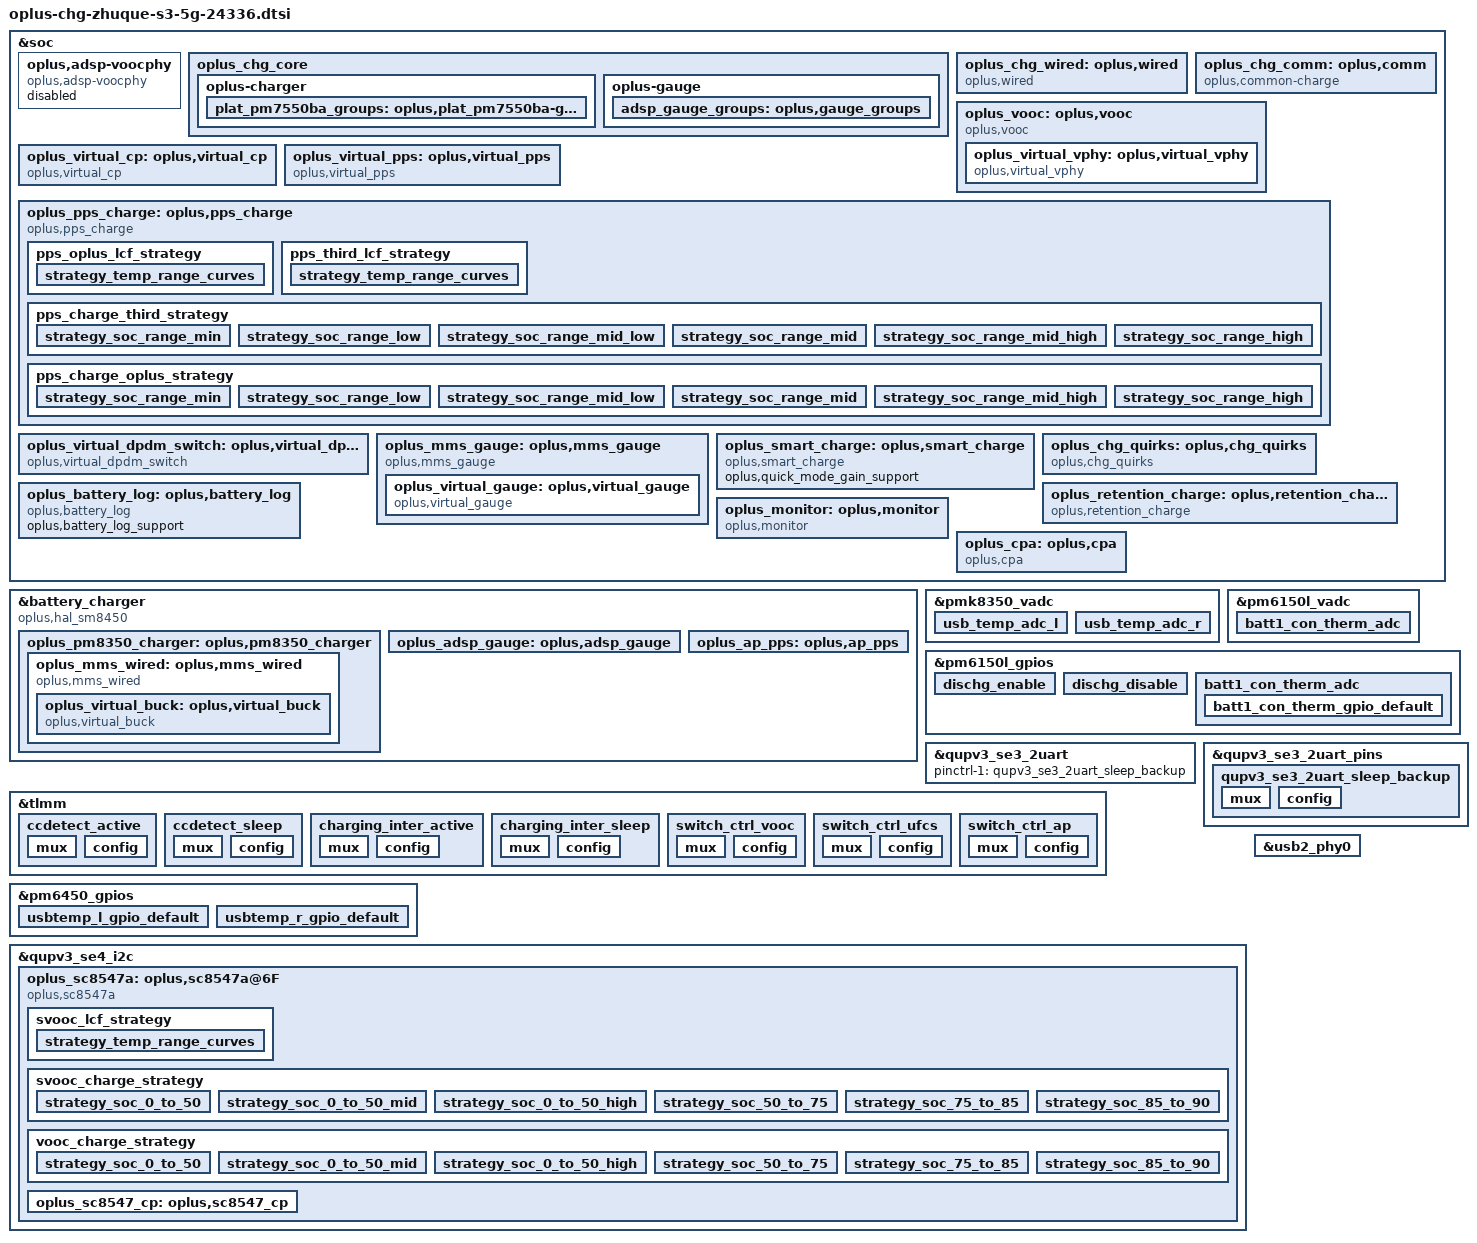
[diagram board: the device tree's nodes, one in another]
#include "oplus_chg.dtsi"

&soc {
	oplus,adsp-voocphy {
		status = "disabled";
		compatible = "oplus,adsp-voocphy";
	};

	oplus_chg_core {
		oplus,chg_framework_v2;
		oplus,smart_charging_screenoff;
		oplus,chg_spec_version = <OPLUS_CHG_SPEC_VER_V3P7>;

		oplus-charger {
			plat_pm7550ba_groups: oplus,plat_pm7550ba-groups {
				functions = <
					OPLUS_IC_FUNC_INIT
					OPLUS_IC_FUNC_EXIT
					OPLUS_IC_FUNC_REG_DUMP
					OPLUS_IC_FUNC_SMT_TEST
					OPLUS_IC_FUNC_BUCK_INPUT_PRESENT
					OPLUS_IC_FUNC_BUCK_INPUT_SUSPEND
					OPLUS_IC_FUNC_BUCK_INPUT_IS_SUSPEND
					OPLUS_IC_FUNC_BUCK_OUTPUT_SUSPEND
					OPLUS_IC_FUNC_BUCK_OUTPUT_IS_SUSPEND
					OPLUS_IC_FUNC_BUCK_GET_CC_ORIENTATION
					OPLUS_IC_FUNC_BUCK_GET_CHARGER_TYPE
					OPLUS_IC_FUNC_BUCK_RERUN_BC12
					OPLUS_IC_FUNC_BUCK_QC_DETECT_ENABLE
					OPLUS_IC_FUNC_BUCK_SHIPMODE_ENABLE
					OPLUS_IC_FUNC_BUCK_SET_QC_CONFIG
					OPLUS_IC_FUNC_BUCK_SET_PD_CONFIG
					OPLUS_IC_FUNC_BACKUP_SOC
					OPLUS_IC_FUNC_GET_SHUTDOWN_SOC
					OPLUS_IC_FUNC_GET_TYPEC_MODE
					OPLUS_IC_FUNC_BUCK_SET_ICL
					OPLUS_IC_FUNC_BUCK_GET_ICL
					OPLUS_IC_FUNC_BUCK_SET_FCC
					OPLUS_IC_FUNC_BUCK_SET_FV
					OPLUS_IC_FUNC_BUCK_SET_ITERM
					OPLUS_IC_FUNC_BUCK_SET_RECHG_VOL
					OPLUS_IC_FUNC_BUCK_GET_INPUT_CURR
					OPLUS_IC_FUNC_BUCK_GET_INPUT_VOL
					OPLUS_IC_FUNC_GET_CHARGER_CYCLE
					OPLUS_IC_FUNC_OTG_BOOST_ENABLE
					OPLUS_IC_FUNC_BUCK_GET_VBUS_COLLAPSE_STATUS
					OPLUS_IC_FUNC_GET_OTG_ENABLE
					OPLUS_IC_FUNC_SET_OTG_SWITCH_STATUS
					OPLUS_IC_FUNC_GET_OTG_SWITCH_STATUS
					OPLUS_IC_FUNC_GET_OTG_ONLINE_STATUS
					OPLUS_IC_FUNC_BUCK_GET_HW_DETECT
					OPLUS_IC_FUNC_VOOCPHY_SET_MATCH_TEMP
					OPLUS_IC_FUNC_IS_OPLUS_SVID
					OPLUS_IC_FUNC_BUCK_GET_USB_BTB_TEMP
					OPLUS_IC_FUNC_BUCK_GET_BATT_BTB_TEMP
					OPLUS_IC_FUNC_SET_TYPEC_MODE
					OPLUS_IC_FUNC_GET_TYPEC_ROLE
				>;
				virqs = <
					OPLUS_IC_VIRQ_ERR
					OPLUS_IC_VIRQ_CC_DETECT
					OPLUS_IC_VIRQ_PLUGIN
					OPLUS_IC_VIRQ_CC_CHANGED
					OPLUS_IC_VIRQ_CHG_TYPE_CHANGE
					OPLUS_IC_VIRQ_SVID
					OPLUS_IC_VIRQ_OTG_ENABLE
				>;
			};
		};

		oplus-gauge {
			adsp_gauge_groups: oplus,gauge_groups {
				functions = <
					OPLUS_IC_FUNC_INIT
					OPLUS_IC_FUNC_EXIT
					OPLUS_IC_FUNC_REG_DUMP
					OPLUS_IC_FUNC_SMT_TEST
					OPLUS_IC_FUNC_GAUGE_GET_BATT_VOL
					OPLUS_IC_FUNC_GAUGE_GET_BATT_MAX
					OPLUS_IC_FUNC_GAUGE_GET_BATT_MIN
					OPLUS_IC_FUNC_GAUGE_GET_BATT_CURR
					OPLUS_IC_FUNC_GAUGE_GET_BATT_TEMP
					OPLUS_IC_FUNC_GAUGE_GET_BATT_SOC
					OPLUS_IC_FUNC_GAUGE_GET_BATT_FCC
					OPLUS_IC_FUNC_GAUGE_GET_BATT_CC
					OPLUS_IC_FUNC_GAUGE_GET_BATT_RM
					OPLUS_IC_FUNC_GAUGE_GET_BATT_SOH
					OPLUS_IC_FUNC_GAUGE_GET_BATT_HMAC
					OPLUS_IC_FUNC_GAUGE_SET_BATT_FULL
					OPLUS_IC_FUNC_GAUGE_UPDATE_DOD0
					OPLUS_IC_FUNC_GAUGE_UPDATE_SOC_SMOOTH
					OPLUS_IC_FUNC_GAUGE_GET_CB_STATUS
					OPLUS_IC_FUNC_GAUGE_GET_BATT_NUM
					OPLUS_IC_FUNC_GAUGE_GET_DEVICE_TYPE
					OPLUS_IC_FUNC_GAUGE_GET_DEVICE_TYPE_FOR_VOOC
					OPLUS_IC_FUNC_GAUGE_GET_BATT_FCC
					OPLUS_IC_FUNC_GAUGE_UPDATE
					OPLUS_IC_FUNC_GAUGE_IS_SUSPEND
					OPLUS_IC_FUNC_GAUGE_GET_BATT_AUTH
					OPLUS_IC_FUNC_GAUGE_GET_BCC_PARMS
					OPLUS_IC_FUNC_GAUGE_GET_DEVICE_TYPE_FOR_BCC
					OPLUS_IC_FUNC_GAUGE_GET_DOD0
					OPLUS_IC_FUNC_GAUGE_GET_DOD0_PASSED_Q
					OPLUS_IC_FUNC_GAUGE_GET_QMAX
					OPLUS_IC_FUNC_GAUGE_GET_QMAX_PASSED_Q
					OPLUS_IC_FUNC_GAUGE_GET_DEC_FG_TYPE
					OPLUS_IC_FUNC_GAUGE_GET_DEC_CV_SOH
					OPLUS_IC_FUNC_GAUGE_SET_VCT
					OPLUS_IC_FUNC_GAUGE_GET_VCT
				>;
				virqs = <
					OPLUS_IC_VIRQ_ERR
					OPLUS_IC_VIRQ_OFFLINE
					OPLUS_IC_VIRQ_RESUME
				>;
			};
		};

	};

	oplus_chg_wired: oplus,wired {
		compatible = "oplus,wired";
		oplus,vooc-support;

		oplus_spec,vbatt_pdqc_to_9v_thr = <5000>;
		oplus_spec,pd-iclmax-ma = <1500>;
		oplus_spec,qc-iclmax-ma = <1500>;
		oplus_spec,non-standard-ibatmax-ma = <1000>;
		oplus_spec,input-power-mw = <
			2500		/* OPLUS_WIRED_CHG_MODE_UNKNOWN */
			2500		/* OPLUS_WIRED_CHG_MODE_SDP */
			7500		/* OPLUS_WIRED_CHG_MODE_CDP */
			10000		/* OPLUS_WIRED_CHG_MODE_DCP */
			30000		/* OPLUS_WIRED_CHG_MODE_VOOC */
			13500		/* OPLUS_WIRED_CHG_MODE_QC */
			13500		/* OPLUS_WIRED_CHG_MODE_PD */
		>;
		oplus_spec,led_on-fccmax-ma = <0 883 3300 3300 3300 3300 3300 1000 0>;
		oplus_spec,fccmax-ma-lv = <
			0 1555 2200 2200 2200 2200 2200 2200 0	/* OPLUS_WIRED_CHG_MODE_UNKNOWN */
			0 600  600  600  600  600  600  600  0	/* OPLUS_WIRED_CHG_MODE_SDP */
			0 883 1600 1600 1600 1600 1600 1600 0	/* OPLUS_WIRED_CHG_MODE_CDP */
			0 883 2200 2200 2200 2200 2200 2200 0	/* OPLUS_WIRED_CHG_MODE_DCP */
			0 883 3300 3300 3300 3300 3300 3239 0	/* OPLUS_WIRED_CHG_MODE_VOOC */
			0 883 3300 3300 3300 3300 3300 3239 0	/* OPLUS_WIRED_CHG_MODE_QC */
			0 883 3300 3300 3300 3300 3300 3239 0	/* OPLUS_WIRED_CHG_MODE_PD */
		>;
		oplus_spec,fccmax-ma-hv = <
			0 1555 2200 2200 2200 2200 2200 2200 0	/* OPLUS_WIRED_CHG_MODE_UNKNOWN */
			0 600  600  600  600  600  600  600  0	/* OPLUS_WIRED_CHG_MODE_SDP */
			0 883  1600 1600 1600 1600 1600 1600 0	/* OPLUS_WIRED_CHG_MODE_CDP */
			0 883  2200 2200 2200 2200 2200 2200 0	/* OPLUS_WIRED_CHG_MODE_DCP */
			0 883 2650 3300 3300 3300 3300 3300 0	/* OPLUS_WIRED_CHG_MODE_VOOC */
			0 883  2650 3300 3300 3300 3300 3300 0	/* OPLUS_WIRED_CHG_MODE_QC */
			0 883  2650 3300 3300 3300 3300 3300 0	/* OPLUS_WIRED_CHG_MODE_PD */
		>;

		oplus_spec,cool_down_pdqc_vol_mv = <5000 5000 5000 9000>;
		oplus_spec,cool_down_pdqc_curr_ma = <1200 1500 2000 1500>;
		oplus_spec,cool_down_vooc_curr_ma = <1200 1500 2000 2500 3000 3000>;
		oplus_spec,cool_down_normal_curr_ma = <1200 1500 2000>;

		oplus_spec,vbus_ov_thr_mv = <11000 11000>;
		oplus_spec,vbus_uv_thr_mv = <4300 4300>;

		/* first data is strategy used temp type */
		oplus,vooc_strategy_name = "cgcl";
		oplus,vooc_strategy_data = <OPLUS_STRATEGY_USE_BATT_TEMP
					    0   385 3000 1 0
					    385 420 3000 2 0
					    420 440 2000 2 1>;
	};

	oplus_chg_comm: oplus,comm {
		compatible = "oplus,common-charge";
		oplus_spec,dec_step = <20>;
		oplus_spec,dec-vol-cc-full-thr = <0 400 600 800 1000 1200>;
		oplus_spec,dec-vol-fv-full-mv = <0 20 20 40 40 40>;
		oplus_spec,batt-them-thr = <(-100) 0 50 120 160 350 450 530>;
		oplus_spec,iterm-ma = <321>;
		oplus_spec,fv-mv = <4490 4490 4490 4490 4490 4490 4470 4130 4130>;
		oplus_spec,sw-fv-mv = <4440 4440 4440 4440 4440 4440 4420 4080 4080>;
		oplus_spec,hw-fv-inc-mv = <0 18 18 18 18 18 18 18 0>;
		oplus_spec,sw-over-fv-mv = <4500 4500 4500 4500 4500 4500 4480 4140 4140>;
		oplus_spec,sw-over-fv-dec-mv = <8>;
		oplus_spec,non-standard-sw-fv-mv = <3930>;
		oplus_spec,non-standard-fv-mv = <3980>;
		oplus_spec,non-standard-hw-fv-inc-mv = <18>;
		oplus_spec,non-standard-sw-over-fv-mv = <3990>;
		oplus_spec,non-standard-vbatdet-mv = <3680>;
		oplus_spec,wired-vbatdet-mv = <0 4200 4300 4400 4400 4400 4375 4030 0>;
		/* oplus_spec,wls-vbatdet-mv = <0 3675 4235 4370 4370 4370 4030 0>; */
		oplus_spec,fcc-gear-thr-mv = <4180>;
		oplus_spec,vbatt-ov-thr-mv = <4600>;

		oplus_spec,full_pre_ffc_judge;
		oplus_spec,full-pre-ffc-mv = <4485>;
		oplus_spec,ffc-temp-thr = <120 210 350 430>;
		oplus_spec,wired-ffc-step-max = <2>;
		oplus_spec,wired-ffc-fv-mv = <4630 4630>;
		oplus_spec,wired-ffc-fv-cutoff-mv = <4535 4535 4520 4535 4535 4495>;

		oplus_spec,removed_bat_decidegc = <390>;

		oplus_spec,wired-ffc-fcc-ma = <1500 1500 1500
					       1000  1390  1000>;
		oplus_spec,wired-ffc-fcc-cutoff-ma = <1300 1300 1300
						      900 1290 900>;

		oplus_spec,vbat_uv_thr_mv = <3300>;
		oplus_spec,vbat_charging_uv_thr_mv = <3200>;

		/*If use subboard NTC as battery temp, config it as 20, otherwise 0 */
		oplus_spec,tbatt_power_off_cali_temp = <0>;
		oplus,vooc_show_ui_soc_decimal;
		oplus_spec,poweroff_high_batt_temp = <720>;
		oplus_spec,poweroff_emergency_batt_temp = <770>;
		oplus,ui_soc_decimal_speedmin = <20>;

		oplus,gauge_stuck_jump_support;
		oplus,gauge_stuck_threshold = <15>;
		oplus,gauge_stuck_time = <50>;

		oplus,smooth_switch;
		oplus,reserve_chg_soc = <2>;
	};

	oplus_vooc: oplus,vooc {
		compatible = "oplus,vooc";
		oplus,vooc_ic = <&oplus_virtual_vphy>;

		oplus_spec,vooc_soc_range = <50 75 85>;
		oplus_spec,vooc_temp_range = <50 120 180 350 450>;

		oplus,vooc_data_width = <7>;
		oplus,vooc_curr_max = <CP_CURR_LIMIT_7BIT_9_0A>;  /* 45W: 11V 4.1A */
		oplus,vooc_project = <21>; /* 45W 11v4.1A */
		oplus,vooc_curr_table_type = <VOOC_CP_CURR_TABLE>;
		oplus,vooc_power_max_w = <45>;
		oplus,voocphy_support = <2>; /* AP_SINGL_CP_VOOCPHY */
		oplus,support_fake_vooc_check;
		oplus,subboard_ntc_abnormal_current = <4000>;

		oplus,abnormal_adapter_current = <CURR_LIMIT_7BIT_7_5A CURR_LIMIT_7BIT_7_5A
						CURR_LIMIT_7BIT_5_0A CURR_LIMIT_7BIT_5_0A
						CURR_LIMIT_7BIT_4_0A CURR_LIMIT_7BIT_4_0A
						CURR_LIMIT_7BIT_3_0A CURR_LIMIT_7BIT_3_0A
						CURR_LIMIT_7BIT_2_0A CURR_LIMIT_7BIT_2_0A>;


		/* first data is strategy used temp type */
		oplus,general_strategy_name = "cgcl";
		oplus,general_strategy_data = < OPLUS_STRATEGY_USE_SHELL_TEMP
						0   400 CURR_LIMIT_7BIT_7_5A 1 0
						390 420 CURR_LIMIT_7BIT_5_0A 2 0
						410 430 CURR_LIMIT_7BIT_4_0A 3 1
						420 440 CURR_LIMIT_7BIT_3_0A 3 2 >;

		oplus_virtual_vphy: oplus,virtual_vphy {
			compatible = "oplus,virtual_vphy";
			oplus,vphy_ic = <&oplus_sc8547a>;
			oplus,dpdm_switch_ic = <&oplus_virtual_dpdm_switch>;

			oplus,ic_type = <OPLUS_CHG_IC_VIRTUAL_VPHY>;
			oplus,ic_index = <0>;
		};
	};

	oplus_virtual_cp: oplus,virtual_cp {
		compatible = "oplus,virtual_cp";

		oplus,ic_type = <OPLUS_CHG_IC_VIRTUAL_CP>;
		oplus,ic_index = <0>;

		oplus,cp_ic = <&oplus_sc8547_cp>;
		oplus,input_curr_max_ma = <3000>;

		oplus,cp_ic_connect = <OPLUS_CHG_IC_CONNECT_PARALLEL>;
		oplus,main_cp = <0>;
	};

	oplus_virtual_pps: oplus,virtual_pps {
		compatible = "oplus,virtual_pps";

		oplus,ic_type = <OPLUS_CHG_IC_VIRTUAL_PPS>;
		oplus,ic_index = <0>;
		oplus,pps_ic = <&oplus_ap_pps>;
	};
	oplus_pps_charge: oplus,pps_charge {
		compatible = "oplus,pps_charge";
		oplus,pps_ic = <&oplus_virtual_pps>;
		oplus,cp_ic = <&oplus_virtual_cp>;
		oplus,dpdm_switch_ic = <&oplus_virtual_dpdm_switch>;
		oplus,target_vbus_mv = <11000>;
		oplus,curr_max_ma = <3000>;
		oplus,lift_vbus_use_cpvout;
		oplus,process_close_cp_item;
		oplus,curr_max_ma_percent = <2000 /* 75% ibus */
					     1000 /* 85% ibus */>;
		oplus,pps_warm_allow_vol = <4000>;
		oplus,pps_warm_allow_soc = <50>;
		oplus,pps_strategy_normal_current = <3000>;
		oplus,pps_over_high_or_low_current = <3000>;
		oplus,pps_timeout_third = <15145>;
		oplus,pps_timeout_oplus = <15145>;
		oplus,pps_ibat_over_third = <7400>;
		oplus,pps_ibat_over_oplus = <7400>;
		oplus,pps_full_cool_sw_vbat = <4490>;
		oplus,pps_full_normal_sw_vbat = <4490>;
		oplus,pps_full_normal_hw_vbat = <4500>;
		oplus,pps_full_ffc_vbat = <4510>;
		oplus,pps_full_warm_vbat = <4130>;
		oplus,pps_full_cool_sw_vbat_third = <4490>;
		oplus,pps_full_normal_sw_vbat_third= <4490>;
		oplus,pps_full_normal_hw_vbat_third = <4500>;
		oplus,pps_current_change_timeout = <100>;

		oplus,curve_strategy_name = "pps_ufcs_curve_v2";
		oplus,pps_r_default = <120 10 10 15 15 15 15>;
		oplus,pps_rmos_mohm = <4>;
		oplus,pps_exit_ms = <500>;
		oplus,pps_r_limit = <280 200 140 90 50>;
		oplus,pps_strategy_batt_high_temp = <410 420 430 400 410 420>;
		oplus,pps_strategy_high_current = <3000 2000 2000 3000 3000 3000>;
		oplus,pps_little_cool_high_temp = <210>;
		oplus,pps_charge_strategy_soc = <0 20 35 55 75 85 85>;
		oplus,pps_charge_strategy_temp = <0 50 120 160 350 440 510>;

		pps_oplus_lcf_strategy {
			oplus,temp_type = <OPLUS_STRATEGY_USE_SHELL_TEMP>;
			oplus,temp_range = <0 50 120 160 210 350 440>;

			strategy_temp_range_curves {
				strategy_temp_range_t0 =	<452 4510 0
								 427 4500 0
								 402 4490 0
								 377 4480 0
								 352 4470 1>;
				strategy_temp_range_t1 =	<474 4510 0
								 439 4505 0
								 404 4490 0
								 369 4480 0
								 334 4470 1>;
				strategy_temp_range_t2 =	<950 4540 0
								 900 4535 0
								 800 4520 0
								 700 4510 0
								 550 4500 1>;
				strategy_temp_range_t3 =	<950 4540 0
								 900 4535 0
								 800 4520 0
								 700 4510 0
								 550  4500 1>;
				strategy_temp_range_t4 =	<1340 4540 0
								 1290 4535 0
								 1190 4520 0
								 1090 4510 0
								 940  4500 1>;
				strategy_temp_range_t5 =	<2204 4540 0
								 2154 4535 0
								 2054 4520 0
								 1954 4510 0
								 1804 4500 1>;
			};
		};

		pps_third_lcf_strategy {
			oplus,temp_type = <OPLUS_STRATEGY_USE_SHELL_TEMP>;
			oplus,temp_range = <0 50 120 160 210 350 440>;

			strategy_temp_range_curves {
				strategy_temp_range_t0 =	<452 4510 0
								 427 4500 0
								 402 4490 0
								 377 4480 0
								 352 4470 1>;
				strategy_temp_range_t1 =	<474 4510 0
								 439 4505 0
								 404 4490 0
								 369 4480 0
								 334 4470 1>;
				strategy_temp_range_t2 =	<950 4540 0
								 900 4535 0
								 800 4520 0
								 700 4510 0
								 550 4500 1>;
				strategy_temp_range_t3 =	<950 4540 0
								 900 4535 0
								 800 4520 0
								 700 4510 0
								 550  4500 1>;
				strategy_temp_range_t4 =	<1340 4540 0
								 1290 4535 0
								 1190 4520 0
								 1090 4510 0
								 940  4500 1>;
				strategy_temp_range_t5 =	<2204 4540 0
								 2154 4535 0
								 2054 4520 0
								 1954 4510 0
								 1804 4500 1>;
			};
		};
		pps_charge_third_strategy {
			oplus,temp_type = <OPLUS_STRATEGY_USE_SHELL_TEMP>;
			oplus,soc_range = <0 20 35 55 75 85 90>;
			oplus,temp_range = <0 50 120 160 210 350 440 510>;

			strategy_soc_range_min {
				strategy_temp_little_cold =	<11000 4150 1900 0 0
								11000 4150 1500 0 0
								11000 4480 1300 0 0
								11000 4490 1000 1 0>;
				strategy_temp_cool =		<11000 4150 2800 0 0
								11000 4150 2500 0 0
								11000 4150 2000 0 0
								11000 4480 1900 0 0
								11000 4480 1500 0 0
								11000 4490 1000 1 0>;
				strategy_temp_little_cool =	<11000 4310 3000 0 0
								11000 4310 2500 0 0
								11000 4480 2200 0 0
								11000 4480 2000 0 0
								11000 4480 1500 0 0
								11000 4490 1000 1 0>;
				strategy_temp_little_cool_high =	<11000 4310 3000 0 0
								11000 4310 2500 0 0
								11000 4480 2200 0 0
								11000 4480 2000 0 0
								11000 4480 1500 0 0
								11000 4490 1000 1 0>;
				strategy_temp_normal_low =	<11000 4360 3000 0 0
								11000 4360 2500 0 0
								11000 4480 2200 0 0
								11000 4480 2000 0 0
								11000 4480 1500 0 0
								11000 4490 1000 1 0>;
				strategy_temp_normal_high =	<11000 4360 3000 0 0
								11000 4360 2500 0 0
								11000 4460 2200 0 0
								11000 4460 2000 0 0
								11000 4460 1500 0 0
								11000 4470 1000 1 0>;
				strategy_temp_warm =		<11000 4120 1600 0 0
								11000 4120 1500 0 0
								11000 4130 1000 1 0>;
			};
			strategy_soc_range_low {
				strategy_temp_little_cold =	<11000 4150 1900 0 0
								11000 4150 1500 0 0
								11000 4480 1300 0 0
								11000 4490 1000 1 0>;
				strategy_temp_cool =		<11000 4150 2800 0 0
								11000 4150 2500 0 0
								11000 4150 2000 0 0
								11000 4480 1900 0 0
								11000 4480 1500 0 0
								11000 4490 1000 1 0>;
				strategy_temp_little_cool =	<11000 4310 3000 0 0
								11000 4310 2500 0 0
								11000 4480 2200 0 0
								11000 4480 2000 0 0
								11000 4480 1500 0 0
								11000 4490 1000 1 0>;
				strategy_temp_little_cool_high =	<11000 4310 3000 0 0
								11000 4310 2500 0 0
								11000 4480 2200 0 0
								11000 4480 2000 0 0
								11000 4480 1500 0 0
								11000 4490 1000 1 0>;
				strategy_temp_normal_low =	<11000 4360 3000 0 0
								11000 4360 2500 0 0
								11000 4480 2200 0 0
								11000 4480 2000 0 0
								11000 4480 1500 0 0
								11000 4490 1000 1 0>;
				strategy_temp_normal_high =	<11000 4360 3000 0 0
								11000 4360 2500 0 0
								11000 4460 2200 0 0
								11000 4460 2000 0 0
								11000 4460 1500 0 0
								11000 4470 1000 1 0>;
				strategy_temp_warm =		<11000 4120 1600 0 0
								11000 4120 1500 0 0
								11000 4130 1000 1 0>;

			};
			strategy_soc_range_mid_low {
				strategy_temp_little_cold =	<11000 4150 1900 0 0
								11000 4150 1500 0 0
								11000 4480 1300 0 0
								11000 4490 1000 1 0>;
				strategy_temp_cool =		<11000 4150 2500 0 0
								11000 4150 2000 0 0
								11000 4480 1900 0 0
								11000 4480 1500 0 0
								11000 4490 1000 1 0>;
				strategy_temp_little_cool =	<11000 4310 3000 0 0
								11000 4310 2500 0 0
								11000 4480 2200 0 0
								11000 4480 2000 0 0
								11000 4480 1500 0 0
								11000 4490 1000 1 0>;
				strategy_temp_little_cool_high =	<11000 4310 3000 0 0
								11000 4310 2500 0 0
								11000 4480 2200 0 0
								11000 4480 2000 0 0
								11000 4480 1500 0 0
								11000 4490 1000 1 0>;
				strategy_temp_normal_low =	<11000 4360 3000 0 0
								11000 4360 2500 0 0
								11000 4480 2200 0 0
								11000 4480 2000 0 0
								11000 4480 1500 0 0
								11000 4490 1000 1 0>;
				strategy_temp_normal_high =	<11000 4360 3000 0 0
								11000 4360 2500 0 0
								11000 4460 2200 0 0
								11000 4460 2000 0 0
								11000 4460 1500 0 0
								11000 4470 1000 1 0>;
				strategy_temp_warm =		<11000 4120 1600 0 0
								11000 4120 1500 0 0
								11000 4130 1000 1 0>;

			};
			strategy_soc_range_mid {
				strategy_temp_little_cold =	<11000 4490 1000 1 0>;
				strategy_temp_cool =		<11000 4480 1500 0 0
								11000 4490 1000 1 0>;
				strategy_temp_little_cool =	<11000 4480 2000 0 0
								11000 4480 1500 0 0
								11000 4490 1000 1 0>;
				strategy_temp_little_cool_high =	<11000 4480 2000 0 0
								11000 4480 1500 0 0
								11000 4490 1000 1 0>;
				strategy_temp_normal_low =	<11000 4480 2000 0 0
								11000 4480 1500 0 0
								11000 4490 1000 1 0>;
				strategy_temp_normal_high =	<11000 4460 2000 0 0
								11000 4460 1500 0 0
								11000 4470 1000 1 0>;
				strategy_temp_warm =		<11000 4130 1000 1 0>;
			};
			strategy_soc_range_mid_high {
				strategy_temp_little_cold =	<11000 4490 1000 1 0>;
				strategy_temp_cool =		<11000 4490 1000 1 0>;
				strategy_temp_little_cool =	<11000 4490 1000 1 0>;
				strategy_temp_little_cool_high =	<11000 4490 1000 1 0>;
				strategy_temp_normal_low =	<11000 4480 1500 0 0
								11000 4490 1000 1 0>;
				strategy_temp_normal_high =	<11000 4460 1500 0 0
								11000 4470 1000 1 0>;
				strategy_temp_warm =		<11000 4130 1000 1 0>;
			};
			strategy_soc_range_high {
				strategy_temp_little_cold =	<11000 4490 1000 1 0>;
				strategy_temp_cool =		<11000 4490 1000 1 0>;
				strategy_temp_little_cool =	<11000 4490 1000 1 0>;
				strategy_temp_little_cool_high =	<11000 4490 1000 1 0>;
				strategy_temp_normal_low =	<11000 4490 1000 1 0>;
				strategy_temp_normal_high =	<11000 4470 1000 1 0>;
				strategy_temp_warm =		<11000 4130 1000 1 0>;
			};
		};

		pps_charge_oplus_strategy {
			oplus,temp_type = <OPLUS_STRATEGY_USE_SHELL_TEMP>;
			oplus,soc_range = <0 20 35 55 75 85 90>;
			oplus,temp_range = <0 50 120 160 210 350 440 510>;

			strategy_soc_range_min {
				strategy_temp_little_cold =	<11000 4150 1900 0 0
								11000 4150 1500 0 0
								11000 4480 1300 0 0
								11000 4490 1000 1 0>;
				strategy_temp_cool =		<11000 4150 2800 0 0
								11000 4150 2500 0 0
								11000 4150 2000 0 0
								11000 4480 1900 0 0
								11000 4480 1500 0 0
								11000 4490 1000 1 0>;
				strategy_temp_little_cool =	<11000 4480 3000 0 0
								11000 4480 2500 0 0
								11000 4480 2200 0 0
								11000 4480 2000 0 0
								11000 4480 1500 0 0
								11000 4490 1000 1 0>;
				strategy_temp_little_cool_high =	<11000 4480 3000 0 0
								11000 4480 2500 0 0
								11000 4480 2200 0 0
								11000 4480 2000 0 0
								11000 4480 1500 0 0
								11000 4490 1000 1 0>;
				strategy_temp_normal_low =	<11000 4480 3000 0 0
								11000 4480 2500 0 0
								11000 4480 2200 0 0
								11000 4480 2000 0 0
								11000 4480 1500 0 0
								11000 4490 1000 1 0>;
				strategy_temp_normal_high =	<11000 4460 3000 0 0
								11000 4460 2500 0 0
								11000 4460 2200 0 0
								11000 4460 2000 0 0
								11000 4460 1500 0 0
								11000 4470 1000 1 0>;
				strategy_temp_warm =		<11000 4120 1600 0 0
								11000 4120 1500 0 0
								11000 4130 1000 1 0>;
			};
			strategy_soc_range_low {
				strategy_temp_little_cold =	<11000 4150 1900 0 0
								11000 4150 1500 0 0
								11000 4480 1300 0 0
								11000 4490 1000 1 0>;
				strategy_temp_cool =		<11000 4150 2800 0 0
								11000 4150 2500 0 0
								11000 4150 2000 0 0
								11000 4480 1900 0 0
								11000 4480 1500 0 0
								11000 4490 1000 1 0>;
				strategy_temp_little_cool =	<11000 4480 3000 0 0
								11000 4480 2500 0 0
								11000 4480 2200 0 0
								11000 4480 2000 0 0
								11000 4480 1500 0 0
								11000 4490 1000 1 0>;
				strategy_temp_little_cool_high =	<11000 4480 3000 0 0
								11000 4480 2500 0 0
								11000 4480 2200 0 0
								11000 4480 2000 0 0
								11000 4480 1500 0 0
								11000 4490 1000 1 0>;
				strategy_temp_normal_low =	<11000 4480 3000 0 0
								11000 4480 2500 0 0
								11000 4480 2200 0 0
								11000 4480 2000 0 0
								11000 4480 1500 0 0
								11000 4490 1000 1 0>;
				strategy_temp_normal_high =	<11000 4460 3000 0 0
								11000 4460 2500 0 0
								11000 4460 2200 0 0
								11000 4460 2000 0 0
								11000 4460 1500 0 0
								11000 4470 1000 1 0>;
				strategy_temp_warm =		<11000 4120 1600 0 0
								11000 4120 1500 0 0
								11000 4130 1000 1 0>;

			};
			strategy_soc_range_mid_low {
				strategy_temp_little_cold =	<11000 4150 1900 0 0
								11000 4150 1500 0 0
								11000 4480 1300 0 0
								11000 4490 1000 1 0>;
				strategy_temp_cool =		<11000 4150 2500 0 0
								11000 4150 2000 0 0
								11000 4480 1900 0 0
								11000 4480 1500 0 0
								11000 4490 1000 1 0>;
				strategy_temp_little_cool =	<11000 4480 3000 0 0
								11000 4480 2500 0 0
								11000 4480 2200 0 0
								11000 4480 2000 0 0
								11000 4480 1500 0 0
								11000 4490 1000 1 0>;
				strategy_temp_little_cool_high =	<11000 4480 3000 0 0
								11000 4480 2500 0 0
								11000 4480 2200 0 0
								11000 4480 2000 0 0
								11000 4480 1500 0 0
								11000 4490 1000 1 0>;
				strategy_temp_normal_low =	<11000 4480 3000 0 0
								11000 4480 2500 0 0
								11000 4480 2200 0 0
								11000 4480 2000 0 0
								11000 4480 1500 0 0
								11000 4490 1000 1 0>;
				strategy_temp_normal_high =	<11000 4460 3000 0 0
								11000 4460 2500 0 0
								11000 4460 2200 0 0
								11000 4460 2000 0 0
								11000 4460 1500 0 0
								11000 4470 1000 1 0>;
				strategy_temp_warm =		<11000 4120 1600 0 0
								11000 4120 1500 0 0
								11000 4130 1000 1 0>;

			};
			strategy_soc_range_mid {
				strategy_temp_little_cold =	<11000 4490 1000 1 0>;
				strategy_temp_cool =		<11000 4480 1500 0 0
								11000 4490 1000 1 0>;
				strategy_temp_little_cool =	<11000 4480 2000 0 0
								11000 4480 1500 0 0
								11000 4490 1000 1 0>;
				strategy_temp_little_cool_high =	<11000 4480 2000 0 0
								11000 4480 1500 0 0
								11000 4490 1000 1 0>;
				strategy_temp_normal_low =	<11000 4480 2000 0 0
								11000 4480 1500 0 0
								11000 4490 1000 1 0>;
				strategy_temp_normal_high =	<11000 4460 2000 0 0
								11000 4460 1500 0 0
								11000 4470 1000 1 0>;
				strategy_temp_warm =		<11000 4130 1000 1 0>;
			};
			strategy_soc_range_mid_high {
				strategy_temp_little_cold =	<11000 4490 1000 1 0>;
				strategy_temp_cool =		<11000 4490 1000 1 0>;
				strategy_temp_little_cool =	<11000 4490 1000 1 0>;
				strategy_temp_little_cool_high =	<11000 4490 1000 1 0>;
				strategy_temp_normal_low =	<11000 4480 1500 0 0
								11000 4490 1000 1 0>;
				strategy_temp_normal_high =	<11000 4460 1500 0 0
								11000 4470 1000 1 0>;
				strategy_temp_warm =		<11000 4130 1000 1 0>;
			};
			strategy_soc_range_high {
				strategy_temp_little_cold =	<11000 4490 1000 1 0>;
				strategy_temp_cool =		<11000 4490 1000 1 0>;
				strategy_temp_little_cool =	<11000 4490 1000 1 0>;
				strategy_temp_little_cool_high =	<11000 4490 1000 1 0>;
				strategy_temp_normal_low =	<11000 4490 1000 1 0>;
				strategy_temp_normal_high =	<11000 4470 1000 1 0>;
				strategy_temp_warm =		<11000 4130 1000 1 0>;
			};
		};
	};

	oplus_virtual_dpdm_switch: oplus,virtual_dpdm_switch {
		compatible = "oplus,virtual_dpdm_switch";
		oplus,ic_type = <OPLUS_CHG_IC_MISC>;
		oplus,ic_index = <0>;
		oplus,switch_ctrl-gpio = <&tlmm 106 0x00>;
		pinctrl-names = "switch_ctrl_ap", "switch_ctrl_vooc", "switch_ctrl_ufcs";
		pinctrl-0 = <&switch_ctrl_ap>;
		pinctrl-1 = <&switch_ctrl_vooc>;
		pinctrl-2 = <&switch_ctrl_ufcs>;
	};

	oplus_mms_gauge: oplus,mms_gauge {
		compatible = "oplus,mms_gauge";
		oplus,gauge_ic = <&oplus_virtual_gauge>;
		oplus,voocphy_ic = <&oplus_virtual_vphy>;
		oplus,topic-update-interval = <5000>;
		//oplus,support_subboard_ntc;

		oplus_virtual_gauge: oplus,virtual_gauge {
			compatible = "oplus,virtual_gauge";
			oplus,gauge_ic = <&oplus_adsp_gauge>;
			oplus,gauge_ic_index = <0>;
			oplus,gauge_ic_func_group =  <&adsp_gauge_groups>;
			oplus,batt_capacity_mah = <6000>;
			oplus,ic_type = <OPLUS_CHG_IC_VIRTUAL_GAUGE>;
			oplus,ic_index = <0>;
		};
	};

	oplus_smart_charge: oplus,smart_charge {
		compatible = "oplus,smart_charge";
		oplus,quick_mode_gain_support;
	};

	oplus_chg_quirks: oplus,chg_quirks {
		compatible = "oplus,chg_quirks";
	};
	oplus_retention_charge: oplus,retention_charge {
		compatible = "oplus,retention_charge";
		oplus,topic-update-interval = <5000>;
		oplus,support_retention_name = "oplus_retention_quirks";
	};

	oplus_battery_log: oplus,battery_log {
		compatible = "oplus,battery_log";
		oplus,battery_log_support;
	};

	oplus_monitor: oplus,monitor {
		compatible = "oplus,monitor";
		oplus,topic-update-interval = <60000>;
		track,fast_chg_break_t_thd = <1000>;
		track,general_chg_break_t_thd = <200>;
		track,voocphy_type = <2>;
		track,wired_max_power = <45000>;
		track,wired_fast_chg_scheme = <2>;
	};
};

&battery_charger {
	compatible = "oplus,hal_sm8450";

	qcom,pmic_ftm_vph = "/sys/bus/spmi/drivers/pmic-spmi/0-00/c42d000.qcom,spmi:qcom,pmk8550@0:vadc@9000/iio:device0/in_voltage_pm7550ba_vph_pwr_input";
	qcom,pmic_ftm_vbat = "/sys/bus/spmi/drivers/pmic-spmi/0-00/c42d000.qcom,spmi:qcom,pmk8550@0:vadc@9000/iio:device0/in_voltage_pm7550ba_vbat_sns_qbg_input";

	//oplus,voocphy_bidirect_cp_support;
	oplus,chg_ops = "plat-pmic";
	oplus,otg_boost_src = <0>; /* 0:plat_pmic 1:external */
	oplus,batt_num = <1>;
	oplus,otg_scheme = <1>; /* 0:cid 1:ccdetect_gpio 2:switch */
	oplus,ic_type = <OPLUS_CHG_IC_BUCK>;
	oplus,ic_index = <0>;

	/* QCOM QBG full param, depend on adapter type and temp_region */
	oplus,batt_full_method_new;
	oplus,batt_full_temp = <(-100) 120 350 440>;
	oplus,batt_full_para = <1000 1000 1000 1000      /* normal pd qc */
				1000 1800 1800 1800      /* svooc */
				1880 1880 1880 1880      /* oplus ufcs */
				1880 1880 1880 1880      /* oplus pps */
				1880 1880 1880 1880      /* third ufcs */
				1000 1880 1880 1000      /* third pps */
				1600 1600 1600 1600>;    /* ffc */

	pinctrl-names = "default";
	pinctrl-0 = <&batt1_con_therm_gpio_default>;
	io-channels = <&pm6150l_vadc ADC5_GPIO1_100K_PU>;
	io-channel-names = "batt1_con_therm_adc";

	oplus_pm8350_charger: oplus,pm8350_charger {
		oplus,ic_type = <OPLUS_CHG_IC_BUCK>;
		oplus,ic_index = <0>;

		oplus_mms_wired: oplus,mms_wired {
			compatible = "oplus,mms_wired";
			oplus,buck_ic = <&oplus_virtual_buck>;
			oplus,voocphy_ic = <&oplus_virtual_vphy>;
			oplus,usbtemp_batttemp_gap = <10>;
			oplus,adc_info_name = "855";
			oplus,topic-update-interval = <5000>;

			high-temp-scheme;
			oplus,support_usbtemp_protect_v2;
			oplus_spec,usbtemp_batt_temp_low = <50>;
			oplus_spec,usbtemp_batt_temp_high = <50>;
			oplus_spec,usbtemp_batt_temp_over_hot = <60>;
			oplus_spec,usbtemp_ntc_temp_low = <57>;
			oplus_spec,usbtemp_ntc_temp_high = <69>;
			oplus_spec,usbtemp_temp_gap_low_with_batt_temp = <7>;
			oplus_spec,usbtemp_temp_gap_with_batt_temp_in_over_hot = <15>;
			oplus_spec,usbtemp_temp_gap_high_with_batt_temp = <12>;
			oplus_spec,usbtemp_temp_gap_low_without_batt_temp = <12>;
			oplus_spec,usbtemp_temp_gap_high_without_batt_temp = <24>;
			oplus_spec,usbtemp_rise_fast_temp_low = <3>;
			oplus_spec,usbtemp_rise_fast_temp_high = <3>;
			oplus_spec,usbtemp_rise_fast_temp_count_low = <30>;
			oplus_spec,usbtemp_rise_fast_temp_count_high = <20>;
			oplus_spec,usbtemp_cool_down_ntc_low = <54>;
			oplus_spec,usbtemp_cool_down_ntc_high = <65>;
			oplus_spec,usbtemp_cool_down_gap_low = <12>;
			oplus_spec,usbtemp_cool_down_gap_high = <20>;
			oplus_spec,usbtemp_cool_down_recover_ntc_low = <48>;
			oplus_spec,usbtemp_cool_down_recover_ntc_high = <60>;
			oplus_spec,usbtemp_cool_down_recover_gap_low = <6>;
			oplus_spec,usbtemp_cool_down_recover_gap_high = <15>;

		oplus_virtual_buck: oplus,virtual_buck {
			compatible = "oplus,virtual_buck";
			oplus,buck_ic = <&oplus_pm8350_charger>;
			oplus,buck_ic_index = <0>;
			oplus,buck_ic_connect = <OPLUS_CHG_IC_CONNECT_PARALLEL>;
			oplus,main_charger = <0>;
			oplus,buck_ic_current_ratio = <100>;
			oplus,buck_ic_func_group = <&plat_pm7550ba_groups>;

			oplus,ic_type = <OPLUS_CHG_IC_VIRTUAL_BUCK>;
			oplus,ic_index = <0>;
			oplus,usbtemp_conversion_ratio = <10>;

			oplus,uart_tx-gpio = <&tlmm 22 0x00>;
			oplus,uart_rx-gpio = <&tlmm 23 0x00>;
			oplus,ccdetect-gpio = <&tlmm 104 0x00>;
			oplus,dischg-gpio = <&pm6150l_gpios 11 0x00>;
			//oplus,ship-gpio = <&tlmm 146 0x00>;
			pinctrl-names = "dischg_enable", "dischg_disable",
			"ccdetect_active", "ccdetect_sleep",
			"usbtemp_l_gpio_default", "usbtemp_r_gpio_default";

			pinctrl-0 = <&dischg_enable>;
			pinctrl-1 = <&dischg_disable>;
			pinctrl-2 = <&ccdetect_active>;
			pinctrl-3 = <&ccdetect_sleep>;
			pinctrl-4 = <&usbtemp_l_gpio_default>;
			pinctrl-5 = <&usbtemp_r_gpio_default>;

			io-channels = <&pmk8350_vadc PM6450_ADC7_AMUX3_GPIO4_100K_PU>,
				      <&pmk8350_vadc PM6450_ADC7_AMUX4_GPIO5_100K_PU>;
			io-channel-names = "usb_temp_adc_l",
					   "usb_temp_adc_r";
			};
		};
	};

	oplus_adsp_gauge: oplus,adsp_gauge {
		oplus,ic_type = <OPLUS_CHG_IC_GAUGE>;
		oplus,ic_index = <0>;
	};

	oplus_ap_pps: oplus,ap_pps {
		oplus,ic_type = <OPLUS_CHG_IC_PPS>;
		oplus,ic_index = <0>;
	};
};

&pmk8350_vadc {
	usb_temp_adc_l {
		reg = <PM6450_ADC7_AMUX3_GPIO4_100K_PU>;
                label = "usb_temp_adc_l";
                qcom,pre-scaling = <1 1>;
                qcom,hw-settle-time = <200>;
                qcom,scale-fn-type = <OPLUS_ADC_SCALE_HW_CALIB_DEFAULT>;
	};

	usb_temp_adc_r{
		reg = <PM6450_ADC7_AMUX4_GPIO5_100K_PU>;
                label = "usb_temp_adc_r";
                qcom,pre-scaling = <1 1>;
                qcom,hw-settle-time = <200>;
                qcom,scale-fn-type = <OPLUS_ADC_SCALE_HW_CALIB_DEFAULT>;
	};
};

&pm6150l_vadc {
	batt1_con_therm_adc {
		reg = <ADC5_GPIO1_100K_PU>;
		label = "batt1_con_therm_adc";
		qcom,pre-scaling = <1 1>;
		qcom,ratiometric;
		qcom,hw-settle-time = <200>;
		qcom,scale-fn-type = <OPLUS_ADC_SCALE_HW_CALIB_THERM_100K_PULLUP>;
	};
};

&pm6150l_gpios {
	dischg_enable: dischg_enable {
		pins = "gpio11";
		function = "normal";
		bias-disable;
		power-source = <0>;
		output-high;
		qcom,drive-strength = <2>;
	};

	dischg_disable: dischg_disable {
		pins = "gpio11";
		function = "normal";
		bias-disable;
		power-source = <0>;
		output-low;
		qcom,drive-strength = <2>;
	};

	batt1_con_therm_adc {
		batt1_con_therm_gpio_default: batt1_con_therm_gpio_default {
			pins = "gpio5";
			bias-high-impedance;
		};
	};
};

&qupv3_se3_2uart {
	pinctrl-1 = <&qupv3_se3_2uart_sleep_backup>;
	status = "ok";
};

&qupv3_se3_2uart_pins {
	qupv3_se3_2uart_sleep_backup:qupv3_se3_2uart_sleep_backup {
		mux {
			pins = "gpio22", "gpio23";
			function = "gpio";
		};

		config {
			pins = "gpio22", "gpio23";
			drive-strength = <2>;
			bias-disable;
			input-enable;
		};
	};
};

&tlmm {
	ccdetect_active: ccdetect_active {
		mux {
			pins = "gpio104";
			function = "gpio";
		};

		config {
			pins = "gpio104";
			drive-strength = <2>;
			input-enable;
			//bias-pull-up; /*PULL UP*/
			bias-disable;
		};
	};

	ccdetect_sleep: ccdetect_sleep {
		mux {
			pins = "gpio104";
			function = "gpio";
		};

		config {
			pins = "gpio104";
			drive-strength = <2>;
			//output-low;
			//bias-pull-down; /*PULL DOWN*/
			input-enable;
			bias-disable;
		};
	};

	charging_inter_active: charging_inter_active {
		mux {
			pins = "gpio67";
			function = "gpio";
		};
		config {
			pins = "gpio67";
			bias-pull-up; /* NO pull */
			drive-strength = <2>; /* 2 MA */
			input-enable;
		};
	};

	charging_inter_sleep: charging_inter_sleep {
		mux {
			pins = "gpio67"; /* SC8547A_INT*/
			function = "gpio";
		};
		config {
			pins = "gpio67";
			drive-strength = <2>; /* 2 MA */
		};
	};
	switch_ctrl_vooc: switch_ctrl_vooc {
		mux {
			pins = "gpio106";
			function = "gpio";
		};
		config {
			pins = "gpio106";
			bias-pull-up; /* NO pull */
			drive-strength = <2>; /* 2 MA */
			output-high;
		};
	};

	switch_ctrl_ufcs: switch_ctrl_ufcs {
		mux {
			pins = "gpio106";
			function = "gpio";
		};
		config {
			pins = "gpio106";
			bias-pull-down; /* NO pull */
			drive-strength = <2>; /* 2 MA */
			output-low;
		};
	};

	switch_ctrl_ap: switch_ctrl_ap {
		mux {
			pins = "gpio106";
			function = "gpio";
		};
		config {
			pins = "gpio106";
			bias-pull-down; /* NO pull */
			drive-strength = <2>; /* 2 MA */
			output-low;
		};
	};
};

&pm6450_gpios {
	usbtemp_l_gpio_default: usbtemp_l_gpio_default {
		pins = "gpio4"; //GPIO 4
		function = "normal"; //normal
		bias-high-impedance; //DISABLE GPIO3 for ADC
		bias-disable;
	};

	usbtemp_r_gpio_default: usbtemp_r_gpio_default {
		pins = "gpio5"; //GPIO 5
		function = "normal"; //normal
		bias-high-impedance; //DISABLE GPIO4 for ADC
		bias-disable;
	};
};
&qupv3_se4_i2c {
	status = "okay";
	qcom,clk-freq-out = <400000>;
	qcom,request-cpu-qos;
	oplus_sc8547a: oplus,sc8547a@6F {
		status = "okay";
		compatible = "oplus,sc8547a";
		reg = <0x6F>;

		ocp_reg = <0xd>;
		ovp_reg = <0x36>;
		vbus_ovp_reg = /bits/ 8 <0x5A>;  /* vbus ovp: 10.5v */
		vooc_vbus_ovp_reg = /bits/ 8 <0x64>;  /* vbus ovp: 11v */

		oplus,use_vooc_phy;
		oplus_spec,irq_gpio = <&tlmm 67 0x00>;
		pinctrl-names = "charging_inter_active", "charging_inter_sleep";
		pinctrl-0 = <&charging_inter_active>;
		pinctrl-1 = <&charging_inter_sleep>;

		oplus,ic_type = <OPLUS_CHG_IC_VPHY>;
		oplus,ic_index = <0>;
		oplus,vooc-version = <VOOC_VERSION_5_0>;
		oplus_spec,voocphy_current_default = <41>;

		oplus_spec,svooc_cool_down_current_limit = <82 20 20 24 30 34 40 44 50 54 60 64 70 74 82>;
		oplus_spec,vooc_cool_down_current_limit = <73 20 20 24 30 34 40 44 50 54 60 64 70 74>;

		oplus_spec,vooc_multistep_initial_batt_temp = <1000>;
		oplus_spec,fastchg_timeout_time_init = <151450>;
		oplus_spec,vooc_little_cool_temp = <160>;
		oplus_spec,vooc_little_cool_high_temp = <210>;
		oplus_spec,vooc_cool_temp = <120>;
		oplus_spec,vooc_little_cold_temp = <50>;
		oplus_spec,vooc_normal_low_temp = <350>;
		oplus_spec,vooc_strategy_normal_current = <146>;
		oplus_spec,vooc_normal_to_little_cool_current = <100>;
		oplus_spec,vooc_over_high_temp = <510>;
		oplus_spec,vooc_low_temp = <0>;

		oplus_spec,vooc_high_temp = <500>;
		oplus_spec,vooc_low_soc = <0>;
		oplus_spec,vooc_high_soc = <90>;
		oplus_spec,vooc_normal_high_temp = <440>;
		oplus_spec,vooc_warm_vol_thr = <4000>;
		oplus_spec,vooc_warm_soc_thr = <50>;

		oplus_spec,vooc_strategy1_batt_high_temp0 = <385>;
		oplus_spec,vooc_strategy1_batt_high_temp1 = <395>;
		oplus_spec,vooc_strategy1_batt_high_temp2 = <420>;
		oplus_spec,vooc_strategy1_batt_low_temp2 = <410>;
		oplus_spec,vooc_strategy1_batt_low_temp1 = <385>;
		oplus_spec,vooc_strategy1_batt_low_temp0 = <375>;

		oplus_spec,vooc_strategy1_high_current0 = <82>;
		oplus_spec,vooc_strategy1_high_current1 = <60>;
		oplus_spec,vooc_strategy1_high_current2 = <40>;
		oplus_spec,vooc_strategy1_low_current2 = <40>;
		oplus_spec,vooc_strategy1_low_current1 = <60>;
		oplus_spec,vooc_strategy1_low_current0 = <82>;

		oplus_spec,vooc_strategy1_high_current0_vooc = <30>;
		oplus_spec,vooc_strategy1_high_current1_vooc = <30>;
		oplus_spec,vooc_strategy1_high_current2_vooc = <30>;
		oplus_spec,vooc_strategy1_low_current2_vooc = <30>;
		oplus_spec,vooc_strategy1_low_current1_vooc = <30>;
		oplus_spec,vooc_strategy1_low_current0_vooc = <30>;

		oplus_spec,voocphy_req_freq = <2208000 2208000 2208000 2208000>;
		oplus_spec,voocphy_freq_mincore = <2208000>;
		oplus_spec,voocphy_freq_midcore = <2208000>;
		oplus_spec,voocphy_freq_maxcore = <2208000>;
		oplus_spec,voocphy_current_change_timeout = <100>;
		oplus_spec,copycat_vooc_support;
		oplus_spec,copycat_vooc_accuracy_value = <105>;

		oplus_spec,voocphy_ibat_over_current = <9600>;
		oplus_spec,voocphy_svooc_cp_max_ibus = <4500>;
		oplus_spec,voocphy_vooc_cp_max_ibus = <4500>;
		oplus_spec,voocphy_cp_max_ibus = <4500>;

		oplus_spec,vooc_little_cold_full_voltage = <4510>;
		oplus_spec,vooc_cool_full_voltage = <4510>;
		oplus_spec,vooc_little_cool_full_voltage = <4540>;
		oplus_spec,vooc_little_cool_high_full_voltage = <4540>;
		oplus_spec,vooc_warm_full_voltage = <4130>;
		oplus_spec,vooc_1time_full_voltage = <4550>;
		oplus_spec,vooc_ntime_full_voltage = <4540>;
		oplus_spec,low_curr_full_t1 = <120>;
		oplus_spec,low_curr_full_t2 = <350>;
		oplus_spec,low_curr_full_t3 = <430>;

		svooc_batt_sys_curve = <0 1 0 1 0 0 0	// 4000mA
					1 1 1 1 0 0 0	// 4604mV
					0 0 1 1 0 1 0	// 2600mA
					1 1 1 1 0 0 0	// 4604mV
					0 0 0 1 0 1 1	// 1100mA
					1 1 1 1 0 0 0>;	// 4604mV

		vooc_batt_sys_curve =  <0 1 0 1 0 0 0	// 4000mA
					1 1 1 1 0 0 0	// 4604mV
					0 0 1 1 0 1 0	// 2600mA
					1 1 1 1 0 0 0	// 4604mV
					0 0 0 1 0 1 1	// 1100mA
					1 1 1 1 0 0 0>;	// 4604mV

		oplus_spec,soc_range = <0 20 35 55 75 85 90>;

		svooc_lcf_strategy {
			oplus,temp_type = <OPLUS_STRATEGY_USE_SHELL_TEMP>;
			oplus,temp_range = <0 50 120 160 210 380 440>;

			strategy_temp_range_curves {
				strategy_temp_range_t0 =	<452 4510 0
								 427 4500 0
								 402 4490 0
								 377 4480 0
								 352 4470 1>;
				strategy_temp_range_t1 =	<474 4510 0
								 439 4505 0
								 404 4490 0
								 369 4480 0
								 334 4470 1>;
				strategy_temp_range_t2 =	<950 4540 0
								 900 4535 0
								 800 4520 0
								 700 4510 0
								 550 4500 1>;
				strategy_temp_range_t3 =	<950 4540 0
								 900 4535 0
								 800 4520 0
								 700 4510 0
								 550  4500 1>;
				strategy_temp_range_t4 =	<1340 4540 0
								 1290 4535 0
								 1190 4520 0
								 1090 4510 0
								 940  4500 1>;
				strategy_temp_range_t5 =	<2204 4540 0
								 2154 4535 0
								 2054 4520 0
								 1954 4510 0
								 1804 4500 1>;
			};
		};
	svooc_charge_strategy {
			strategy_soc_0_to_50 { /* 0 ~ 20 */
				strategy_temp_little_cold =	<4150 19 0 0 0
								 4150 15 0 0 0
								 4500 13 0 0 0
								 4510 10 1 0 0>;
				strategy_temp_cool =	<4150 28 0 0 0
								 4150 25 0 0 0
								 4150 20 0 0 0
								 4500 19 0 0 0
								 4500 15 0 0 0
								 4510 10 1 0 0>;
				strategy_temp_little_cool =	<4100 41 0 0 0
								 4100 40 0 0 0
								 4100 35 0 0 0
								 4310 33 0 0 0
								 4310 30 0 0 0
								 4310 25 0 0 0
								 4530 22 0 0 0
								 4530 20 0 0 0
								 4530 15 0 0 0
								 4540 10 1 0 0>;
				strategy_temp_little_cool_high = <4100 41 0 0 0
								 4100 40 0 0 0
								 4100 35 0 0 0
								 4310 33 0 0 0
								 4310 30 0 0 0
								 4310 25 0 0 0
								 4530 22 0 0 0
								 4530 20 0 0 0
								 4530 15 0 0 0
								 4540 10 1 0 0>;
				strategy_temp_normal_low =	<4150 41 0 0 0
								 4150 40 0 0 0
								 4150 35 0 0 0
								 4360 33 0 0 0
								 4360 30 0 0 0
								 4360 25 0 0 0
								 4530 22 0 0 0
								 4530 20 0 0 0
								 4530 15 0 0 0
								 4540 10 1 0 0>;
				strategy_temp_normal_high =	<4150 41 0 0 0
								 4150 40 0 0 0
								 4150 35 0 0 0
								 4360 33 0 0 0
								 4360 30 0 0 0
								 4360 25 0 0 0
								 4530 22 0 0 0
								 4530 20 0 0 0
								 4530 15 0 0 0
								 4540 12 1 0 0>;
				strategy_temp_warm = <4120 16 0 0 0
								 4120 15 0 0 0
								 4130 10 1 0 0>;
			};

			strategy_soc_0_to_50_mid { /* 21 ~ 35 */
				strategy_temp_little_cold =	<4150 19 0 0 0
								 4150 15 0 0 0
								 4500 13 0 0 0
								 4510 10 1 0 0>;
				strategy_temp_cool =	<4150 28 0 0 0
								 4150 25 0 0 0
								 4150 20 0 0 0
								 4500 19 0 0 0
								 4500 15 0 0 0
								 4510 10 1 0 0>;
				strategy_temp_little_cool =	<4100 41 0 0 0
								 4100 40 0 0 0
								 4100 35 0 0 0
								 4310 33 0 0 0
								 4310 30 0 0 0
								 4310 25 0 0 0
								 4530 22 0 0 0
								 4530 20 0 0 0
								 4530 15 0 0 0
								 4540 10 1 0 0>;
				strategy_temp_little_cool_high = <4100 41 0 0 0
								 4100 40 0 0 0
								 4100 35 0 0 0
								 4310 33 0 0 0
								 4310 30 0 0 0
								 4310 25 0 0 0
								 4530 22 0 0 0
								 4530 20 0 0 0
								 4530 15 0 0 0
								 4540 10 1 0 0>;
				strategy_temp_normal_low = <4150 41 0 0 0
								 4150 40 0 0 0
								 4150 35 0 0 0
								 4360 33 0 0 0
								 4360 30 0 0 0
								 4360 25 0 0 0
								 4530 22 0 0 0
								 4530 20 0 0 0
								 4530 15 0 0 0
								 4540 10 1 0 0>;
				strategy_temp_normal_high =	<4150 41 0 0 0
								 4150 40 0 0 0
								 4150 35 0 0 0
								 4360 33 0 0 0
								 4360 30 0 0 0
								 4360 25 0 0 0
								 4530 22 0 0 0
								 4530 20 0 0 0
								 4530 15 0 0 0
								 4540 12 1 0 0>;
				strategy_temp_warm = <4120 16 0 0 0
								 4120 15 0 0 0
								 4130 10 1 0 0>;
			};

			strategy_soc_0_to_50_high { /* 36 ~ 55 */
				strategy_temp_little_cold =	<4150 19 0 0 0
								 4150 15 0 0 0
								 4500 13 0 0 0
								 4510 10 1 0 0>;
				strategy_temp_cool =	<4150 25 0 0 0
								 4150 20 0 0 0
								 4500 19 0 0 0
								 4500 15 0 0 0
								 4510 10 1 0 0>;
				strategy_temp_little_cool =	<4310 30 0 0 0
								 4310 25 0 0 0
								 4530 22 0 0 0
								 4530 20 0 0 0
								 4530 15 0 0 0
								 4540 10 1 0 0>;
				strategy_temp_little_cool_high = <4310 30 0 0 0
								 4310 25 0 0 0
								 4530 22 0 0 0
								 4530 20 0 0 0
								 4530 15 0 0 0
								 4540 10 1 0 0>;
				strategy_temp_normal_low =	<4150 41 0 0 0
								 4150 40 0 0 0
								 4150 35 0 0 0
								 4360 33 0 0 0
								 4360 30 0 0 0
								 4360 25 0 0 0
								 4530 22 0 0 0
								 4530 20 0 0 0
								 4530 15 0 0 0
								 4540 10 1 0 0>;
				strategy_temp_normal_high =	<4150 41 0 0 0
								 4150 40 0 0 0
								 4150 35 0 0 0
								 4360 33 0 0 0
								 4360 30 0 0 0
								 4360 25 0 0 0
								 4530 22 0 0 0
								 4530 20 0 0 0
								 4530 15 0 0 0
								 4540 12 1 0 0>;
				strategy_temp_warm = <4120 16 0 0 0
								 4120 15 0 0 0
								 4130 10 1 0 0>;
			};

			strategy_soc_50_to_75 { /* 56 ~ 75 */
				strategy_temp_little_cold =	<4510 10 1 0 0>;
				strategy_temp_cool =	<4500 15 0 0 0
								 4510 10 1 0 0>;
				strategy_temp_little_cool =	<4530 20 0 0 0
								 4530 15 0 0 0
								 4540 10 1 0 0>;
				strategy_temp_little_cool_high = <4530 20 0 0 0
								 4530 15 0 0 0
								 4540 10 1 0 0>;
				strategy_temp_normal_low =	<4360 25 0 0 0
								 4530 22 0 0 0
								 4530 20 0 0 0
								 4530 15 0 0 0
								 4540 10 1 0 0>;
				strategy_temp_normal_high =	<4360 25 0 0 0
								 4530 22 0 0 0
								 4530 20 0 0 0
								 4530 15 0 0 0
								 4540 12 1 0 0>;
				strategy_temp_warm = <4130 10 1 0 0>;
			};

			strategy_soc_75_to_85 {	/*76 ~ 85*/
				strategy_temp_little_cold =	<4510 10 1 0 0>;
				strategy_temp_cool =	<4510 10 1 0 0>;
				strategy_temp_little_cool =	<4530 15 0 0 0
								 4540 10 1 0 0>;
				strategy_temp_little_cool_high = <4530 15 0 0 0
								 4540 10 1 0 0>;
				strategy_temp_normal_low =	<4530 15 0 0 0
								 4540 10 1 0 0>;
				strategy_temp_normal_high =	<4530 15 0 0 0
								 4540 12 1 0 0>;
				strategy_temp_warm = <4130 10 1 0 0>;
			};

			strategy_soc_85_to_90 { /*86 ~ 95*/
				strategy_temp_little_cold =	<4510 10 1 0 0>;
				strategy_temp_cool =	<4510 10 1 0 0>;
				strategy_temp_little_cool =	<4540 10 1 0 0>;
				strategy_temp_little_cool_high = <4540 10 1 0 0>;
				strategy_temp_normal_low =	<4540 10 1 0 0>;
				strategy_temp_normal_high =	<4540 12 1 0 0>;
				strategy_temp_warm = <4130 10 1 0 0>;
			};
		};


		vooc_charge_strategy {
			strategy_soc_0_to_50 {
				strategy_temp_little_cold =	<4150 30 0 0 0
								 4500 26 0 0 0
								 4510 20 1 0 0>;
				strategy_temp_cool =		<4500 30 0 0 0
								 4510 20 1 0 0>;
				strategy_temp_little_cool =	<4530 30 0 0 0
								 4540 20 1 0 0>;
				strategy_temp_little_cool_high = <4530 30 0 0 0
								 4540 20 1 0 0>;
				strategy_temp_normal_low =	<4530 30 0 0 0
								 4540 20 1 0 0>;
				strategy_temp_normal_high =	<4530 30 0 0 0
								 4540 24 1 0 0>;
				strategy_temp_warm =		<4120 30 0 0 0
								 4130 20 1 0 0>;
			};

			strategy_soc_0_to_50_mid {
				strategy_temp_little_cold =	<4150 30 0 0 0
								 4500 26 0 0 0
								 4510 20 1 0 0>;
				strategy_temp_cool =		<4500 30 0 0 0
								 4510 20 1 0 0>;
				strategy_temp_little_cool =	<4530 30 0 0 0
								 4540 20 1 0 0>;
				strategy_temp_little_cool_high = <4530 30 0 0 0
								 4540 20 1 0 0>;
				strategy_temp_normal_low =	<4530 30 0 0 0
								 4540 20 1 0 0>;
				strategy_temp_normal_high =	<4530 30 0 0 0
								 4540 24 1 0 0>;
				strategy_temp_warm =		<4120 30 0 0 0
								 4130 20 1 0 0>;
			};

			strategy_soc_0_to_50_high {
				strategy_temp_little_cold =	<4150 30 0 0 0
								 4500 26 0 0 0
								 4510 20 1 0 0>;
				strategy_temp_cool =		<4500 30 0 0 0
								 4510 20 1 0 0>;
				strategy_temp_little_cool =	<4530 30 0 0 0
								 4540 20 1 0 0>;
				strategy_temp_little_cool_high = <4530 30 0 0 0
								 4540 20 1 0 0>;
				strategy_temp_normal_low =	<4530 30 0 0 0
								 4540 20 1 0 0>;
				strategy_temp_normal_high =	<530 30 0 0 0
								 4540 24 1 0 0>;
				strategy_temp_warm =		<4120 30 0 0 0
								 4130 20 1 0 0>;
			};

			strategy_soc_50_to_75 {
				strategy_temp_little_cold =	<4510 20 1 0 0>;
				strategy_temp_cool =		<4500 30 0 0 0
								 4510 20 1 0 0>;
				strategy_temp_little_cool =	<4530 30 0 0 0
								 4540 20 1 0 0>;
				strategy_temp_little_cool_high = <4530 30 0 0 0
								 4540 20 1 0 0>;
				strategy_temp_normal_low =	<4530 30 0 0 0
								 4540 20 1 0 0>;
				strategy_temp_normal_high =	<4530 30 0 0 0
								 4540 24 1 0 0>;
				strategy_temp_warm =		<4130 20 1 0 0>;
			};

			strategy_soc_75_to_85 {
				strategy_temp_little_cold =	<4510 20 1 0 0>;
				strategy_temp_cool =		<4510 20 1 0 0>;
				strategy_temp_little_cool =	<4530 30 0 0 0
								 4540 20 1 0 0>;
				strategy_temp_little_cool_high = <4530 30 0 0 0
								 4540 20 1 0 0>;
				strategy_temp_normal_low =	<4530 30 0 0 0
								 4540 20 1 0 0>;
				strategy_temp_normal_high =	<4530 30 0 0 0
								 4540 24 1 0 0>;
				strategy_temp_warm = 		<4130 20 1 0 0>;
			};

			strategy_soc_85_to_90 {
				strategy_temp_little_cold =	<4510 20 1 0 0>;
				strategy_temp_cool =		<4510 20 1 0 0>;
				strategy_temp_little_cool =	<4540 20 1 0 0>;
				strategy_temp_little_cool_high = <4540 20 1 0 0>;
				strategy_temp_normal_low =	<4540 20 1 0 0>;
				strategy_temp_normal_high =	<4540 24 1 0 0>;
				strategy_temp_warm = 		<4130 20 1 0 0>;
			};
		};

		oplus_sc8547_cp: oplus,sc8547_cp {
			oplus,ic_type = <OPLUS_CHG_IC_CP>;
			oplus,ic_index = <0>;
		};
	};
};

&soc {
	oplus_cpa: oplus,cpa {
		compatible = "oplus,cpa";
		oplus,protocol_list = <CHG_PROTOCOL_VOOC 45
					   CHG_PROTOCOL_PPS 33
					   CHG_PROTOCOL_PD 18
				       CHG_PROTOCOL_QC 18>;
		oplus,default_protocol_list = <CHG_PROTOCOL_VOOC
					       CHG_PROTOCOL_PPS
					       CHG_PROTOCOL_PD>;
	};
};

&usb2_phy0 {
	qcom,param-override-seq =
		<0x87 0x6c
		0x0d 0x70
		0x04 0x74
		0x70 0x78>;

	qcom,param-override-seq-host =
		<0x87 0x6c
		0x05 0x70
		0x04 0x74
		0x70 0x78>;
};
